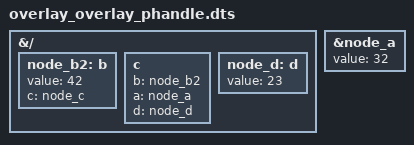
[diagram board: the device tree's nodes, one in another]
/*
 * Copyright (c) 2023 Uwe Kleine-König
 *
 * SPDX-License-Identifier:	GPL-2.0+
 */

/dts-v1/;
/plugin/;

&{/} {
	/* /a already has a label "node_a" in the base dts */
	node_b2: b {
		value = <42>;
		c = <&node_c>;
	};

	c {
		b = <&node_b2>;
		a = <&node_a>;
		d = <&node_d>;
	};

	node_d: d {
		value = <23>;
	};
};

&node_a {
	value = <32>;
};
